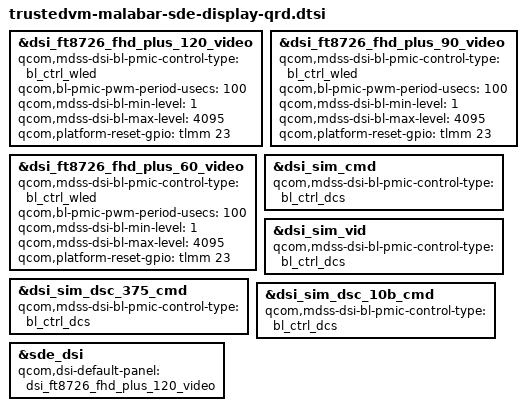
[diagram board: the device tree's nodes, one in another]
// SPDX-License-Identifier: BSD-3-Clause
/*
 * Copyright (c) Qualcomm Technologies, Inc. and/or its subsidiaries.
 */

#include "trustedvm-malabar-sde-display.dtsi"

&dsi_ft8726_fhd_plus_120_video {
	qcom,mdss-dsi-bl-pmic-control-type = "bl_ctrl_wled";
	qcom,bl-pmic-pwm-period-usecs = <100>;
	qcom,mdss-dsi-bl-min-level = <1>;
	qcom,mdss-dsi-bl-max-level = <4095>;
	qcom,platform-reset-gpio = <&tlmm 23 0>;
};

&dsi_ft8726_fhd_plus_90_video {
	qcom,mdss-dsi-bl-pmic-control-type = "bl_ctrl_wled";
	qcom,bl-pmic-pwm-period-usecs = <100>;
	qcom,mdss-dsi-bl-min-level = <1>;
	qcom,mdss-dsi-bl-max-level = <4095>;
	qcom,platform-reset-gpio = <&tlmm 23 0>;
};

&dsi_ft8726_fhd_plus_60_video {
	qcom,mdss-dsi-bl-pmic-control-type = "bl_ctrl_wled";
	qcom,bl-pmic-pwm-period-usecs = <100>;
	qcom,mdss-dsi-bl-min-level = <1>;
	qcom,mdss-dsi-bl-max-level = <4095>;
	qcom,platform-reset-gpio = <&tlmm 23 0>;
};

&dsi_sim_cmd {
	qcom,mdss-dsi-bl-pmic-control-type = "bl_ctrl_dcs";
};

&dsi_sim_vid {
	qcom,mdss-dsi-bl-pmic-control-type = "bl_ctrl_dcs";
};

&dsi_sim_dsc_375_cmd {
	qcom,mdss-dsi-bl-pmic-control-type = "bl_ctrl_dcs";
};

&dsi_sim_dsc_10b_cmd {
	qcom,mdss-dsi-bl-pmic-control-type = "bl_ctrl_dcs";
};

&sde_dsi {
	qcom,dsi-default-panel = <&dsi_ft8726_fhd_plus_120_video>;
};
